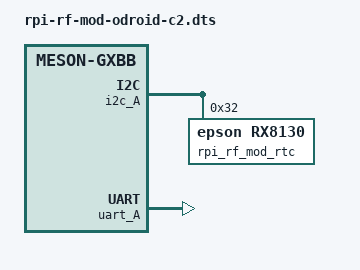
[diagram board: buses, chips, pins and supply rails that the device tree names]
/dts-v1/;
/plugin/;

/*
** Device Tree Overlay for eQ-3 RPI-RF-MOD and
** HM-MOD-RPI-PCB for ODROID-C2
**
** Copyright (c) 2021-2023 Jens Maus <mail@jens-maus.de>
** Licensed under Apache 2.0
**
** LED limitation: the RPI-RF-MOD LEDs use header pins 36 (red),
** 38 (green) and 40 (blue). On ODROID boards pin 38 is a 1.8V
** reference output and pin 40 is an ADC input, so no RGB LED group
** (leds-group-multicolor) can be defined. See
** docs/RPI-RF-MOD-hss-led.md.
*/

/ {
    compatible = "hardkernel,odroid-c2", "amlogic,meson-gxbb";

    // fragment to define settings for the rx8130 RTC clock
    // of the RPI-RF-MOD
    fragment@0 {
        target = <&i2c_A>;
        __overlay__ {
            #address-cells = <1>;
            #size-cells = <0>;
            status = "okay";

            rpi_rf_mod_rtc: rx8130@32 {
                compatible = "epson,rx8130";
                reg = <0x32>;
                status = "okay";
                aux-voltage-chargeable = <1>;
            };
        };
    };

    // fragment to define uart/serial dependencies for
    // generic_raw_uart
    fragment@1 {
        target = <&uart_A>;
        __overlay__ {
            compatible = "pivccu,meson";
            status = "okay";
            pivccu,reset-gpios = <&gpio 102 0>, <&gpio 78 0>; // HM-MOD-RPI-PCB, RPI-RF-MOD
            pivccu,rtc = <&rpi_rf_mod_rtc>;     // RPI-RF-MOD
        };
    };

    // modify /aliases path to make i2c0=i2c_B and i2c1=i2c_A
    // as well as using the rtc of the RPI-RF-MOD as the primary
    // (rtc0) one
    fragment@2 {
        target-path = "/aliases";
        __overlay__ {
            i2c0 = "/soc/bus@c1100000/i2c@87c0";           // @i2c_B
            i2c1 = "/soc/bus@c1100000/i2c@8500";           // @i2c_A
            rtc0 = "/soc/bus@c1100000/i2c@8500/rx8130@32"; // @rpi_rf_mod_rtc
        };
    };
};
